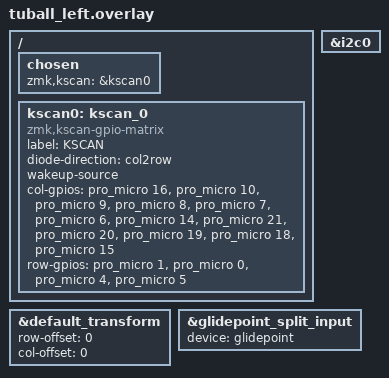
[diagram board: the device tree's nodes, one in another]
#include "tuball.dtsi"
#include "tuball-layouts.dtsi"
#include "glidepoint.dtsi"
#include "split_input_proglide.dtsi"
#include <dt-bindings/zmk/input_transform.h>


&default_transform {
	row-offset = <0>;
	col-offset = <0>;
};

&i2c0 {
    status = "okay";
};

&glidepoint_split_input { // local glidepoint touchpad *split* input device child node
	device = <&glidepoint>;
};
 


/ {
	chosen {
		zmk,kscan = &kscan0;
	};

    kscan0: kscan_0 {
        compatible = "zmk,kscan-gpio-matrix";
        label = "KSCAN";
        diode-direction = "col2row";
	wakeup-source;

        col-gpios
            = <&pro_micro 16 GPIO_ACTIVE_HIGH>
            , <&pro_micro 10 GPIO_ACTIVE_HIGH>
            , <&pro_micro 9 GPIO_ACTIVE_HIGH>
            , <&pro_micro 8 GPIO_ACTIVE_HIGH>
            , <&pro_micro 7 GPIO_ACTIVE_HIGH>
            , <&pro_micro 6 GPIO_ACTIVE_HIGH>
            , <&pro_micro 14 GPIO_ACTIVE_HIGH>
            , <&pro_micro 21 GPIO_ACTIVE_HIGH>
            , <&pro_micro 20 GPIO_ACTIVE_HIGH>
            , <&pro_micro 19 GPIO_ACTIVE_HIGH>
            , <&pro_micro 18 GPIO_ACTIVE_HIGH>
            , <&pro_micro 15 GPIO_ACTIVE_HIGH>
            ;

        row-gpios
            = <&pro_micro 1 (GPIO_ACTIVE_HIGH | GPIO_PULL_DOWN)>
            , <&pro_micro 0 (GPIO_ACTIVE_HIGH | GPIO_PULL_DOWN)>
            , <&pro_micro 4 (GPIO_ACTIVE_HIGH | GPIO_PULL_DOWN)>
            , <&pro_micro 5 (GPIO_ACTIVE_HIGH | GPIO_PULL_DOWN)>
            ;
    };
 
};

